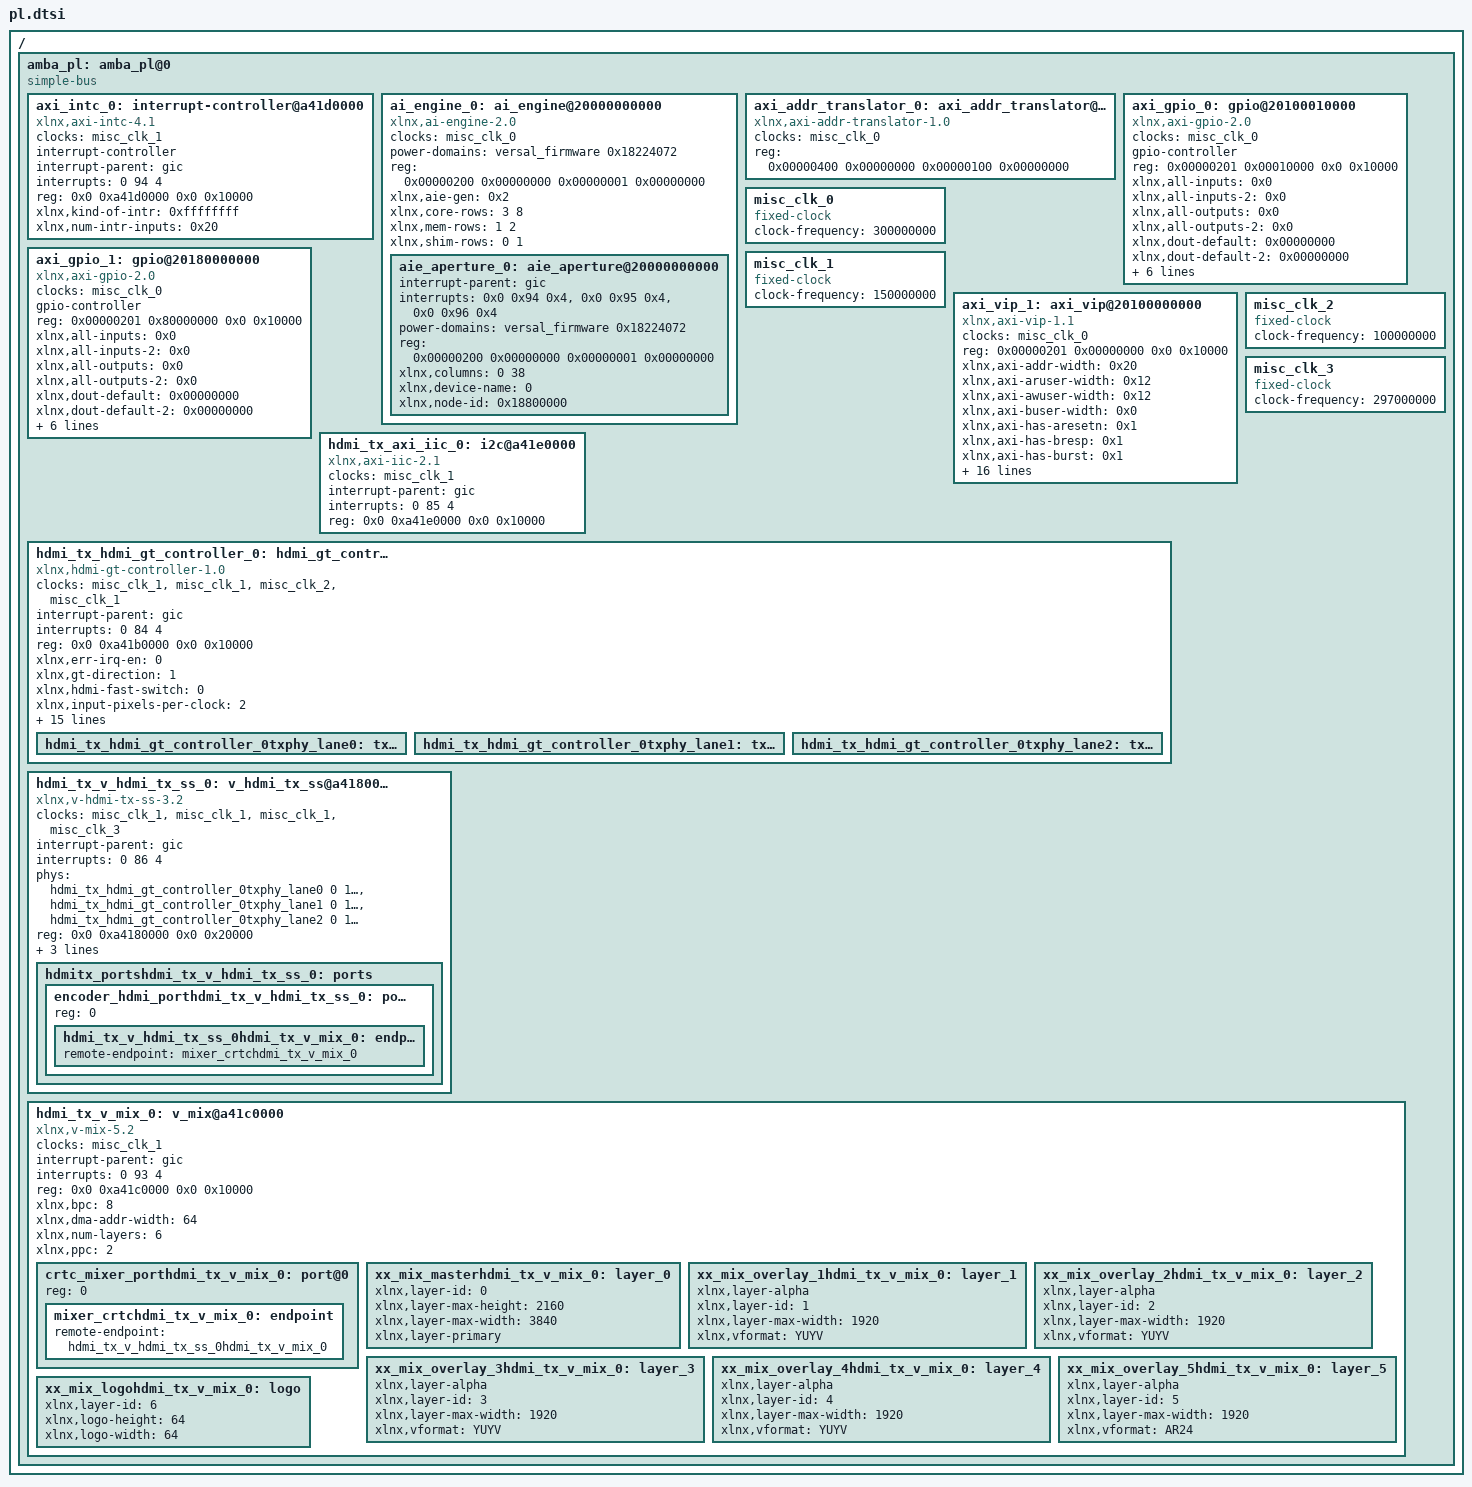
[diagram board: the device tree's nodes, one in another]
/*
 * CAUTION: This file is automatically generated by Xilinx.
 * Version: XSCT 
 * Today is: Thu Oct 17 11:18:41 2024
 */


/ {
	amba_pl: amba_pl@0 {
		#address-cells = <2>;
		#size-cells = <2>;
		compatible = "simple-bus";
		ranges ;
		axi_intc_0: interrupt-controller@a41d0000 {
			#interrupt-cells = <2>;
			clock-names = "s_axi_aclk";
			clocks = <&misc_clk_1>;
			compatible = "xlnx,axi-intc-4.1", "xlnx,xps-intc-1.00.a";
			interrupt-controller ;
			interrupt-names = "irq";
			interrupt-parent = <&gic>;
			interrupts = <0 94 4>;
			reg = <0x0 0xa41d0000 0x0 0x10000>;
			xlnx,kind-of-intr = <0xffffffff>;
			xlnx,num-intr-inputs = <0x20>;
		};
		ai_engine_0: ai_engine@20000000000 {
			#address-cells = <2>;
			#size-cells = <2>;
			clock-names = "aclk0";
			clocks = <&misc_clk_0>;
			compatible = "xlnx,ai-engine-2.0", "xlnx,ai-engine-v2.0";
			power-domains = <&versal_firmware 0x18224072>;
			ranges ;
			reg = <0x00000200 0x00000000 0x00000001 0x00000000>;
			xlnx,aie-gen = /bits/ 8 <0x2>;
			xlnx,core-rows = /bits/ 8 <3 8>;
			xlnx,mem-rows = /bits/ 8 <1 2>;
			xlnx,shim-rows = /bits/ 8 <0 1>;
			aie_aperture_0: aie_aperture@20000000000 {
				#address-cells = <2>;
				#size-cells = <2>;
				interrupt-names = "interrupt1", "interrupt2", "interrupt3";
				interrupt-parent = <&gic>;
				interrupts = <0x0 0x94 0x4>, <0x0 0x95 0x4>, <0x0 0x96 0x4>;
				power-domains = <&versal_firmware 0x18224072>;
				reg = <0x00000200 0x00000000 0x00000001 0x00000000>;
				xlnx,columns = <0 38>;
				xlnx,device-name = <0>;
				xlnx,node-id = <0x18800000>;
			};
		};
                axi_addr_translator_0: axi_addr_translator@40000000000 {
                        clock-names = "aclk";
                        clocks = <&misc_clk_0>;
                        compatible = "xlnx,axi-addr-translator-1.0";
                        reg = <0x00000400 0x00000000 0x00000100 0x00000000>;
                };
		axi_gpio_0: gpio@20100010000 {
			#gpio-cells = <2>;
			clock-names = "s_axi_aclk";
			clocks = <&misc_clk_0>;
			compatible = "xlnx,axi-gpio-2.0", "xlnx,xps-gpio-1.00.a";
			gpio-controller ;
			reg = <0x00000201 0x00010000 0x0 0x10000>;
			xlnx,all-inputs = <0x0>;
			xlnx,all-inputs-2 = <0x0>;
			xlnx,all-outputs = <0x0>;
			xlnx,all-outputs-2 = <0x0>;
			xlnx,dout-default = <0x00000000>;
			xlnx,dout-default-2 = <0x00000000>;
			xlnx,gpio-width = <0x20>;
			xlnx,gpio2-width = <0x20>;
			xlnx,interrupt-present = <0x0>;
			xlnx,is-dual = <0x0>;
			xlnx,tri-default = <0xFFFFFFFF>;
			xlnx,tri-default-2 = <0xFFFFFFFF>;
		};
		misc_clk_0: misc_clk_0 {
			#clock-cells = <0>;
			clock-frequency = <300000000>;
			compatible = "fixed-clock";
		};
		axi_gpio_1: gpio@20180000000 {
			#gpio-cells = <2>;
			clock-names = "s_axi_aclk";
			clocks = <&misc_clk_0>;
			compatible = "xlnx,axi-gpio-2.0", "xlnx,xps-gpio-1.00.a";
			gpio-controller ;
			reg = <0x00000201 0x80000000 0x0 0x10000>;
			xlnx,all-inputs = <0x0>;
			xlnx,all-inputs-2 = <0x0>;
			xlnx,all-outputs = <0x0>;
			xlnx,all-outputs-2 = <0x0>;
			xlnx,dout-default = <0x00000000>;
			xlnx,dout-default-2 = <0x00000000>;
			xlnx,gpio-width = <0x20>;
			xlnx,gpio2-width = <0x20>;
			xlnx,interrupt-present = <0x0>;
			xlnx,is-dual = <0x0>;
			xlnx,tri-default = <0xFFFFFFFF>;
			xlnx,tri-default-2 = <0xFFFFFFFF>;
		};
		misc_clk_1: misc_clk_1 {
			#clock-cells = <0>;
			clock-frequency = <150000000>;
			compatible = "fixed-clock";
		};
		axi_vip_1: axi_vip@20100000000 {
			clock-names = "aclk";
			clocks = <&misc_clk_0>;
			compatible = "xlnx,axi-vip-1.1";
			reg = <0x00000201 0x00000000 0x0 0x10000>;
			xlnx,axi-addr-width = <0x20>;
			xlnx,axi-aruser-width = <0x12>;
			xlnx,axi-awuser-width = <0x12>;
			xlnx,axi-buser-width = <0x0>;
			xlnx,axi-has-aresetn = <0x1>;
			xlnx,axi-has-bresp = <0x1>;
			xlnx,axi-has-burst = <0x1>;
			xlnx,axi-has-cache = <0x1>;
			xlnx,axi-has-lock = <0x1>;
			xlnx,axi-has-prot = <0x1>;
			xlnx,axi-has-qos = <0x1>;
			xlnx,axi-has-region = <0x0>;
			xlnx,axi-has-rresp = <0x1>;
			xlnx,axi-has-wstrb = <0x1>;
			xlnx,axi-interface-mode = <0x2>;
			xlnx,axi-protocol = <0x0>;
			xlnx,axi-rdata-width = <0x20>;
			xlnx,axi-rid-width = <0x0>;
			xlnx,axi-ruser-width = <0x0>;
			xlnx,axi-supports-narrow = <0x0>;
			xlnx,axi-wdata-width = <0x20>;
			xlnx,axi-wid-width = <0x0>;
			xlnx,axi-wuser-width = <0x0>;
		};
		hdmi_tx_axi_iic_0: i2c@a41e0000 {
			#address-cells = <1>;
			#size-cells = <0>;
			clock-names = "s_axi_aclk";
			clocks = <&misc_clk_1>;
			compatible = "xlnx,axi-iic-2.1", "xlnx,xps-iic-2.00.a";
			interrupt-names = "iic2intc_irpt";
			interrupt-parent = <&gic>;
			interrupts = <0 85 4>;
			reg = <0x0 0xa41e0000 0x0 0x10000>;
		};
		hdmi_tx_hdmi_gt_controller_0: hdmi_gt_controller@a41b0000 {
			clock-names = "apb_clk", "axi4lite_aclk", "gt_refclk1_odiv2", "sb_aclk";
			clocks = <&misc_clk_1>, <&misc_clk_1>, <&misc_clk_2>, <&misc_clk_1>;
			compatible = "xlnx,hdmi-gt-controller-1.0";
			interrupt-names = "irq";
			interrupt-parent = <&gic>;
			interrupts = <0 84 4>;
			reg = <0x0 0xa41b0000 0x0 0x10000>;
			xlnx,err-irq-en = <0>;
			xlnx,gt-direction = <1>;
			xlnx,hdmi-fast-switch = <0>;
			xlnx,input-pixels-per-clock = <2>;
			xlnx,nidru = <0>;
			xlnx,nidru-refclk-sel = <2>;
			xlnx,rx-frl-refclk-sel = <2>;
			xlnx,rx-no-of-channels = <4>;
			xlnx,rx-pll-selection = <8>;
			xlnx,rx-protocol = <3>;
			xlnx,rx-refclk-sel = <0>;
			xlnx,transceiver-width = <2>;
			xlnx,tx-buffer-bypass = <1>;
			xlnx,tx-frl-refclk-sel = <2>;
			xlnx,tx-no-of-channels = <4>;
			xlnx,tx-pll-selection = <7>;
			xlnx,tx-protocol = <1>;
			xlnx,tx-refclk-sel = <1>;
			xlnx,use-gt-ch4-hdmi = <1>;
			hdmi_tx_hdmi_gt_controller_0txphy_lane0: tx_axi4s_ch0hdmi_tx_v_hdmi_tx_ss_0 {
				#phy-cells = <4>;
			};
			hdmi_tx_hdmi_gt_controller_0txphy_lane1: tx_axi4s_ch1hdmi_tx_v_hdmi_tx_ss_0 {
				#phy-cells = <4>;
			};
			hdmi_tx_hdmi_gt_controller_0txphy_lane2: tx_axi4s_ch2hdmi_tx_v_hdmi_tx_ss_0 {
				#phy-cells = <4>;
			};
		};
		misc_clk_2: misc_clk_2 {
			#clock-cells = <0>;
			clock-frequency = <100000000>;
			compatible = "fixed-clock";
		};
		hdmi_tx_v_hdmi_tx_ss_0: v_hdmi_tx_ss@a4180000 {
			clock-names = "s_axi_cpu_aclk", "s_axis_audio_aclk", "s_axis_video_aclk", "video_clk";
			clocks = <&misc_clk_1>, <&misc_clk_1>, <&misc_clk_1>, <&misc_clk_3>;
			compatible = "xlnx,v-hdmi-tx-ss-3.2", "xlnx,v-hdmi-tx-ss-3.1";
			interrupt-names = "irq";
			interrupt-parent = <&gic>;
			interrupts = <0 86 4>;
			phy-names = "hdmi-phy0", "hdmi-phy1", "hdmi-phy2";
			phys = <&hdmi_tx_hdmi_gt_controller_0txphy_lane0 0 1 1 1>, <&hdmi_tx_hdmi_gt_controller_0txphy_lane1 0 1 1 1>, <&hdmi_tx_hdmi_gt_controller_0txphy_lane2 0 1 1 1>;
			reg = <0x0 0xa4180000 0x0 0x20000>;
			xlnx,input-pixels-per-clock = <2>;
			xlnx,max-bits-per-component = <8>;
			xlnx,vid-interface = <0>;
			hdmitx_portshdmi_tx_v_hdmi_tx_ss_0: ports {
				#address-cells = <1>;
				#size-cells = <0>;
				encoder_hdmi_porthdmi_tx_v_hdmi_tx_ss_0: port@0 {
					reg = <0>;
					hdmi_tx_v_hdmi_tx_ss_0hdmi_tx_v_mix_0: endpoint {
						remote-endpoint = <&mixer_crtchdmi_tx_v_mix_0>;
					};
				};
			};
		};
		misc_clk_3: misc_clk_3 {
			#clock-cells = <0>;
			clock-frequency = <297000000>;
			compatible = "fixed-clock";
		};
		hdmi_tx_v_mix_0: v_mix@a41c0000 {
			clock-names = "ap_clk";
			clocks = <&misc_clk_1>;
			compatible = "xlnx,v-mix-5.2", "xlnx,mixer-3.0", "xlnx,mixer-4.0", "xlnx,mixer-5.0";
			interrupt-names = "interrupt";
			interrupt-parent = <&gic>;
			interrupts = <0 93 4>;
			reg = <0x0 0xa41c0000 0x0 0x10000>;
			xlnx,bpc = <8>;
			xlnx,dma-addr-width = <64>;
			xlnx,num-layers = <6>;
			xlnx,ppc = <2>;
			crtc_mixer_porthdmi_tx_v_mix_0: port@0 {
				reg = <0>;
				mixer_crtchdmi_tx_v_mix_0: endpoint {
					remote-endpoint = <&hdmi_tx_v_hdmi_tx_ss_0hdmi_tx_v_mix_0>;
				};
			};
			xx_mix_masterhdmi_tx_v_mix_0: layer_0 {
				xlnx,layer-id = <0>;
				xlnx,layer-max-height = <2160>;
				xlnx,layer-max-width = <3840>;
				xlnx,layer-primary ;
			};
			xx_mix_overlay_1hdmi_tx_v_mix_0: layer_1 {
				xlnx,layer-alpha ;
				xlnx,layer-id = <1>;
				xlnx,layer-max-width = <1920>;
				xlnx,vformat = "YUYV";
			};
			xx_mix_overlay_2hdmi_tx_v_mix_0: layer_2 {
				xlnx,layer-alpha ;
				xlnx,layer-id = <2>;
				xlnx,layer-max-width = <1920>;
				xlnx,vformat = "YUYV";
			};
			xx_mix_overlay_3hdmi_tx_v_mix_0: layer_3 {
				xlnx,layer-alpha ;
				xlnx,layer-id = <3>;
				xlnx,layer-max-width = <1920>;
				xlnx,vformat = "YUYV";
			};
			xx_mix_overlay_4hdmi_tx_v_mix_0: layer_4 {
				xlnx,layer-alpha ;
				xlnx,layer-id = <4>;
				xlnx,layer-max-width = <1920>;
				xlnx,vformat = "YUYV";
			};
			xx_mix_overlay_5hdmi_tx_v_mix_0: layer_5 {
				xlnx,layer-alpha ;
				xlnx,layer-id = <5>;
				xlnx,layer-max-width = <1920>;
				xlnx,vformat = "AR24";
			};
			xx_mix_logohdmi_tx_v_mix_0: logo {
				xlnx,layer-id = <6>;
				xlnx,logo-height = <64>;
				xlnx,logo-width = <64>;
			};
		};
	};
};
